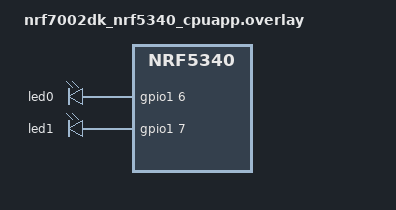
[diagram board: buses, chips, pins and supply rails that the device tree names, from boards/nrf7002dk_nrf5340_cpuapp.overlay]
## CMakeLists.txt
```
#
# Copyright (c) 2021 Nordic Semiconductor ASA
#
# SPDX-License-Identifier: LicenseRef-Nordic-5-Clause
#

cmake_minimum_required(VERSION 3.20.0)

# Set Kconfig root files that will be processed as a first Kconfig for used child images.
set(mcuboot_KCONFIG_ROOT "\\\${ZEPHYR_CONNECTEDHOMEIP_MODULE_DIR}/config/nrfconnect/chip-module/Kconfig.mcuboot.root")
set(multiprotocol_rpmsg_KCONFIG_ROOT "\\\${ZEPHYR_CONNECTEDHOMEIP_MODULE_DIR}/config/nrfconnect/chip-module/Kconfig.multiprotocol_rpmsg.root")
set(hci_ipc_KCONFIG_ROOT "\\\${ZEPHYR_CONNECTEDHOMEIP_MODULE_DIR}/config/nrfconnect/chip-module/Kconfig.hci_ipc.root")

# For prj.conf the CONF_FILE is empty. In other case extract the exact file name from the path string.
if(CONF_FILE)
    get_filename_component(CONF_FILE_NAME ${CONF_FILE} NAME CACHE)
endif()

if(NOT CONF_FILE_NAME STREQUAL "prj_no_dfu.conf")
    set(PM_STATIC_YML_FILE ${CMAKE_CURRENT_SOURCE_DIR}/configuration/${BOARD}/pm_static_dfu.yml)
endif()

if(CONF_FILE_NAME STREQUAL "prj_thread_wifi_switched.conf")
    # TODO: Add Kconfig for adding custom Matter compilation flags
    set(CHIP_CFLAGS "-flto")
endif()

find_package(Zephyr HINTS $ENV{ZEPHYR_BASE})

project(matter-lock)

set(COMMON_ROOT ${ZEPHYR_NRF_MODULE_DIR}/samples/matter/common)
set(NLIO_ROOT ${ZEPHYR_CONNECTEDHOMEIP_MODULE_DIR}/third_party/nlio/repo)
include(${ZEPHYR_CONNECTEDHOMEIP_MODULE_DIR}/config/nrfconnect/app/enable-gnu-std.cmake)
include(${ZEPHYR_CONNECTEDHOMEIP_MODULE_DIR}/src/app/chip_data_model.cmake)

# NORDIC SDK APP START
target_include_directories(app PRIVATE
    src
    ${COMMON_ROOT}/src
    ${NLIO_ROOT}/include
    ${ZEPHYR_CONNECTEDHOMEIP_MODULE_DIR}/zzz_generated/app-common
)

target_sources(app PRIVATE
    src/app_task.cpp
    src/bolt_lock_manager.cpp
    src/main.cpp
    src/zcl_callbacks.cpp
    ${COMMON_ROOT}/src/board/led_widget.cpp
    ${COMMON_ROOT}/src/app/task_executor.cpp
    ${COMMON_ROOT}/src/board/board.cpp
    ${COMMON_ROOT}/src/app/matter_init.cpp
    ${COMMON_ROOT}/src/app/matter_event_handler.cpp
)

if(CONFIG_CHIP_ICD_LIT_SUPPORT)
target_include_directories(app PRIVATE
    src/lit
)

target_sources(app PRIVATE
    src/lit/zap-generated/callback-stub.cpp
    src/lit/zap-generated/IMClusterCommandHandler.cpp
)
else()
target_include_directories(app PRIVATE
    src/sit
)

target_sources(app PRIVATE
    src/sit/zap-generated/callback-stub.cpp
    src/sit/zap-generated/IMClusterCommandHandler.cpp
)
endif()

if(CONFIG_CHIP_OTA_REQUESTOR OR CONFIG_MCUMGR_TRANSPORT_BT)
    target_sources(app PRIVATE ${COMMON_ROOT}/src/dfu/ota/ota_util.cpp)
endif()

if(CONFIG_CHIP_NUS)
    target_sources(app PRIVATE ${COMMON_ROOT}/src/bt_nus/bt_nus_service.cpp)
endif()

if(CONFIG_MCUMGR_TRANSPORT_BT)
    zephyr_library_link_libraries(MCUBOOT_BOOTUTIL)
    target_sources(app PRIVATE ${COMMON_ROOT}/src/dfu/smp/dfu_over_smp.cpp)
endif()

if(CONFIG_THREAD_WIFI_SWITCHING)
    target_sources(app PRIVATE src/thread_wifi_switch.cpp)

    # Enable link-time optimization for the app and WPA supplicant libraries
    target_compile_options(app PRIVATE -flto)
    target_compile_options(..__nrf__modules__hostap PRIVATE -flto)
endif()

if(CONFIG_NCS_SAMPLE_MATTER_OPERATIONAL_KEYS_MIGRATION_TO_ITS)
    target_sources(app PRIVATE ${COMMON_ROOT}/src/migration/migration_manager.cpp)
endif()

if(CONFIG_CHIP_ICD_LIT_SUPPORT)
chip_configure_data_model(app
    INCLUDE_SERVER
    BYPASS_IDL
    GEN_DIR src/lit/zap-generated
    ZAP_FILE ${CMAKE_CURRENT_SOURCE_DIR}/src/lock-lit.zap
)
else()
chip_configure_data_model(app
    INCLUDE_SERVER
    BYPASS_IDL
    GEN_DIR src/sit/zap-generated
    ZAP_FILE ${CMAKE_CURRENT_SOURCE_DIR}/src/lock.zap
)
endif()
# NORDIC SDK APP END
```

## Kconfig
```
#
# Copyright (c) 2021 Nordic Semiconductor
#
# SPDX-License-Identifier: LicenseRef-Nordic-5-Clause
#

mainmenu "Matter Lock sample application"

config STATE_LEDS
	bool "Use LEDs to indicate the device state"
	default y
	help
	  Use LEDs to render the current state of the device such as the progress of commissioning of
	  the device into a network or the factory reset initiation. Note that setting this option to
	  'n' does not disable the LED indicating the state of the simulated bolt.

rsource "${ZEPHYR_BASE}/../modules/lib/matter/config/nrfconnect/chip-module/Kconfig.features"
rsource "${ZEPHYR_BASE}/../modules/lib/matter/config/nrfconnect/chip-module/Kconfig.defaults"
source "Kconfig.zephyr"
```

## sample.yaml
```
sample:
  description: Matter Lock example
  name: Matter Lock
tests:
  sample.matter.lock.debug:
    sysbuild: true
    build_only: true
    integration_platforms:
      - nrf52840dk/nrf52840
      - nrf5340dk/nrf5340/cpuapp
      - nrf7002dk/nrf5340/cpuapp
      - nrf7002dk/nrf5340/cpuapp/nrf7001
      - nrf54l15dk/nrf54l15/cpuapp
      - nrf54l15dk/nrf54l15/cpuapp/ns
      - nrf54h20dk/nrf54h20/cpuapp
    platform_allow: nrf52840dk/nrf52840 nrf5340dk/nrf5340/cpuapp nrf7002dk/nrf5340/cpuapp
      nrf7002dk/nrf5340/cpuapp/nrf7001 nrf54l15dk/nrf54l15/cpuapp
      nrf54h20dk/nrf54h20/cpuapp nrf54l15dk/nrf54l15/cpuapp/ns
    tags: sysbuild ci_samples_matter
  sample.matter.lock.release:
    sysbuild: true
    build_only: true
    extra_args: FILE_SUFFIX=release
    integration_platforms:
      - nrf52840dk/nrf52840
      - nrf5340dk/nrf5340/cpuapp
      - nrf7002dk/nrf5340/cpuapp
      - nrf7002dk/nrf5340/cpuapp/nrf7001
      - nrf54l15dk/nrf54l15/cpuapp
      - nrf54h20dk/nrf54h20/cpuapp
    platform_allow: nrf52840dk/nrf52840 nrf5340dk/nrf5340/cpuapp nrf7002dk/nrf5340/cpuapp
      nrf7002dk/nrf5340/cpuapp/nrf7001 nrf54l15dk/nrf54l15/cpuapp
      nrf54h20dk/nrf54h20/cpuapp
    tags: sysbuild ci_samples_matter
  sample.matter.lock.lto:
    sysbuild: true
    build_only: true
    extra_args: CONFIG_LTO=y CONFIG_ISR_TABLES_LOCAL_DECLARATION=y
    integration_platforms:
      - nrf52840dk/nrf52840
      - nrf5340dk/nrf5340/cpuapp
      - nrf7002dk/nrf5340/cpuapp
      - nrf7002dk/nrf5340/cpuapp/nrf7001
      - nrf54l15dk/nrf54l15/cpuapp
    platform_allow: nrf52840dk/nrf52840 nrf5340dk/nrf5340/cpuapp nrf7002dk/nrf5340/cpuapp
      nrf7002dk/nrf5340/cpuapp/nrf7001 nrf54l15dk/nrf54l15/cpuapp
    tags: sysbuild ci_samples_matter
  sample.matter.lock.smp_dfu:
    sysbuild: true
    build_only: true
    extra_args: CONFIG_CHIP_DFU_OVER_BT_SMP=y
    integration_platforms:
      - nrf52840dk/nrf52840
      - nrf5340dk/nrf5340/cpuapp
      - nrf7002dk/nrf5340/cpuapp
      - nrf7002dk/nrf5340/cpuapp/nrf7001
      - nrf54l15dk/nrf54l15/cpuapp
    platform_allow: nrf52840dk/nrf52840 nrf5340dk/nrf5340/cpuapp nrf7002dk/nrf5340/cpuapp
      nrf7002dk/nrf5340/cpuapp/nrf7001 nrf54l15dk/nrf54l15/cpuapp
    tags: sysbuild ci_samples_matter
  sample.matter.lock.no_dfu.no_fd:
    sysbuild: true
    build_only: true
    extra_args: SB_CONFIG_MATTER_OTA=n
    integration_platforms:
      - nrf21540dk/nrf52840
    platform_allow: nrf21540dk/nrf52840
    tags: sysbuild ci_samples_matter
  sample.matter.lock.thread_wifi_switched.lto.smp_dfu:
    sysbuild: true
    build_only: true
    extra_args: lock_SHIELD=nrf7002ek
      FILE_SUFFIX=thread_wifi_switched SB_CONFIG_WIFI_PATCHES_EXT_FLASH_STORE=y
      SB_CONFIG_MCUBOOT_UPDATEABLE_IMAGES=3 CONFIG_CHIP_DFU_OVER_BT_SMP=y
      SB_CONFIG_WIFI_NRF70=y SB_CONFIG_DFU_MULTI_IMAGE_PACKAGE_WIFI_FW_PATCH=y
    integration_platforms:
      - nrf5340dk/nrf5340/cpuapp
    platform_allow: nrf5340dk/nrf5340/cpuapp
    tags: sysbuild ci_samples_matter
  sample.matter.lock.nus:
    sysbuild: true
    build_only: true
    extra_args: CONFIG_CHIP_NUS=y CONFIG_BT_FIXED_PASSKEY=y CONFIG_CHIP_NUS_FIXED_PASSKEY=112233
    integration_platforms:
      - nrf52840dk/nrf52840
      - nrf5340dk/nrf5340/cpuapp
    platform_allow: nrf52840dk/nrf52840 nrf5340dk/nrf5340/cpuapp nrf54l15dk/nrf54l15/cpuapp
    tags: sysbuild ci_samples_matter
  sample.matter.lock.release.power_consumption:
    sysbuild: true
    build_only: true
    extra_args: FILE_SUFFIX=max_tx_power
    integration_platforms:
      - nrf52840dk/nrf52840
      - nrf5340dk/nrf5340/cpuapp
      - nrf54l15dk/nrf54l15/cpuapp
    platform_allow: nrf52840dk/nrf52840 nrf5340dk/nrf5340/cpuapp nrf54l15dk/nrf54l15/cpuapp
    tags: sysbuild ci_samples_matter
```

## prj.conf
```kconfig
#
# Copyright (c) 2022 Nordic Semiconductor ASA
#
# SPDX-License-Identifier: LicenseRef-Nordic-5-Clause
#

# This sample uses Kconfig.defaults to set options common for all
# samples. This file should contain only options specific for this sample
# or overrides of default values.

# Enable CHIP
CONFIG_CHIP=y
CONFIG_CHIP_PROJECT_CONFIG="src/chip_project_config.h"
# 32774 == 0x8006 (example lock-app)
CONFIG_CHIP_DEVICE_PRODUCT_ID=32774
CONFIG_STD_CPP17=y

# Enable Matter extended announcement and increase duration to 1 hour.
CONFIG_CHIP_BLE_EXT_ADVERTISING=y
CONFIG_CHIP_BLE_ADVERTISING_DURATION=60

# Add support for LEDs and buttons on Nordic development kits
CONFIG_DK_LIBRARY=y

# Bluetooth Low Energy configuration
CONFIG_BT_DEVICE_NAME="MatterLock"

# Suspend devices when the CPU goes into sleep
CONFIG_PM_DEVICE=y

# Other settings
CONFIG_THREAD_NAME=y
CONFIG_MPU_STACK_GUARD=y
CONFIG_RESET_ON_FATAL_ERROR=n
CONFIG_CHIP_LIB_SHELL=y

# Reduce application size
CONFIG_USE_SEGGER_RTT=n
CONFIG_MATTER_LOG_LEVEL_INF=y
CONFIG_CHIP_APP_LOG_LEVEL=3

# Enable Factory Data feature
CONFIG_CHIP_FACTORY_DATA=y
CONFIG_CHIP_FACTORY_DATA_BUILD=y

# Increase system workqueue stack size
CONFIG_SYSTEM_WORKQUEUE_STACK_SIZE=1536

# Enable LIT ICD configuration
CONFIG_CHIP_ICD_LIT_SUPPORT=y
```

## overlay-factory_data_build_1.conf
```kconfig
#
# Copyright (c) 2023 Nordic Semiconductor ASA
#
# SPDX-License-Identifier: LicenseRef-Nordic-5-Clause
#

# Use this overlay to re-generate new PAI and DAC certificates.
# Be sure that chip-cert executable is added to your system PATH.

# Enable building the new factory data
CONFIG_CHIP_FACTORY_DATA=y
CONFIG_CHIP_FACTORY_DATA_BUILD=y
CONFIG_CHIP_FACTORY_DATA_USE_DEFAULT_CERTS=n
CONFIG_CHIP_FACTORY_DATA_CERT_SOURCE_GENERATED=y
CONFIG_CHIP_FACTORY_DATA_MERGE_WITH_FIRMWARE=y
CONFIG_CHIP_DEVICE_GENERATE_ROTATING_DEVICE_UID=n

# Set up the Factory Data
CONFIG_CHIP_DEVICE_SERIAL_NUMBER="1"
CONFIG_CHIP_DEVICE_VENDOR_ID=65521
CONFIG_CHIP_DEVICE_VENDOR_NAME="Nordic Semiconductor ASA"
CONFIG_CHIP_DEVICE_PRODUCT_ID=32774
CONFIG_CHIP_DEVICE_PRODUCT_NAME="Door Lock"
CONFIG_CHIP_DEVICE_MANUFACTURING_DATE="2023-05-30"
CONFIG_CHIP_DEVICE_HARDWARE_VERSION=1
CONFIG_CHIP_DEVICE_HARDWARE_VERSION_STRING="TE1_2023"
CONFIG_CHIP_DEVICE_DISCRIMINATOR=0xE46
CONFIG_CHIP_DEVICE_SPAKE2_PASSCODE=28073715
CONFIG_CHIP_DEVICE_SPAKE2_IT=1000
CONFIG_CHIP_DEVICE_SPAKE2_TEST_VERIFIER="XUQaKLznAVZ+WEWkSTIEJwvjaU/CuWY1qLbRKuS56VEE4Us+aJNGy3B3tLClZWRDAS5yXUgku5pHyFLgVTAKXQIo663Y2L7HvrJh/8jlD0OTNDDLlsnjKdj+l0b2rC3vMg=="
CONFIG_CHIP_DEVICE_ROTATING_DEVICE_UID="0989f27796617e00ff9dc844496dbcf3"
CONFIG_CHIP_DEVICE_ENABLE_KEY="d229322af1412d66ebeda07e0d39b80e"
CONFIG_CHIP_DEVICE_PRODUCT_FINISH="other"
CONFIG_CHIP_DEVICE_PRODUCT_COLOR="aqua"

CONFIG_CHIP_FACTORY_DATA_CERT_SOURCE_USER=y
# Align paths to your local ones
CONFIG_CHIP_FACTORY_DATA_USER_CERTS_DAC_CERT="~/ncs/nrf/samples/matter/lock/factory_data_1/DAC-Cert.der"
CONFIG_CHIP_FACTORY_DATA_USER_CERTS_DAC_KEY="~/ncs/nrf/samples/matter/lock/factory_data_1/DAC-Key.der"
CONFIG_CHIP_FACTORY_DATA_USER_CERTS_PAI_CERT="~/ncs/nrf/samples/matter/lock/factory_data_1//PAI-Cert.der"
```

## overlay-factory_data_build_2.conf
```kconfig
#
# Copyright (c) 2023 Nordic Semiconductor ASA
#
# SPDX-License-Identifier: LicenseRef-Nordic-5-Clause
#

# Use this overlay to re-generate new PAI and DAC certificates.
# Be sure that chip-cert executable is added to your system PATH.

# Enable building the new factory data
CONFIG_CHIP_FACTORY_DATA=y
CONFIG_CHIP_FACTORY_DATA_BUILD=y
CONFIG_CHIP_FACTORY_DATA_USE_DEFAULT_CERTS=n
CONFIG_CHIP_FACTORY_DATA_CERT_SOURCE_GENERATED=y
CONFIG_CHIP_FACTORY_DATA_MERGE_WITH_FIRMWARE=y
CONFIG_CHIP_DEVICE_GENERATE_ROTATING_DEVICE_UID=n

# Set up the Factory Data
CONFIG_CHIP_DEVICE_SERIAL_NUMBER="2"
CONFIG_CHIP_DEVICE_VENDOR_ID=65521
CONFIG_CHIP_DEVICE_VENDOR_NAME="Nordic Semiconductor ASA"
CONFIG_CHIP_DEVICE_PRODUCT_ID=32774
CONFIG_CHIP_DEVICE_PRODUCT_NAME="Door Lock"
CONFIG_CHIP_DEVICE_MANUFACTURING_DATE="2023-05-30"
CONFIG_CHIP_DEVICE_HARDWARE_VERSION=1
CONFIG_CHIP_DEVICE_HARDWARE_VERSION_STRING="TE1_2023"
CONFIG_CHIP_DEVICE_DISCRIMINATOR=0x1fa
CONFIG_CHIP_DEVICE_SPAKE2_PASSCODE=80327003
CONFIG_CHIP_DEVICE_SPAKE2_IT=1000
CONFIG_CHIP_DEVICE_SPAKE2_TEST_VERIFIER="sMpmMvNf6t1TROKCjV9CnYwCMMV7l5YyXX/ajicjG1MEkZx8Ylg73OpW6w+BpfWeFgUBHreWf166zwxaTaY53y6cIFnu9HvWQofN0yKmnRjDZyZpBpb+2pR7bIdqUxcHcw=="
CONFIG_CHIP_DEVICE_ROTATING_DEVICE_UID="462a2785f8536233d6ce0427970fc596"
CONFIG_CHIP_DEVICE_ENABLE_KEY="5a9f1b3e358cc9934900aa6a2a085024"
CONFIG_CHIP_DEVICE_PRODUCT_FINISH="other"
CONFIG_CHIP_DEVICE_PRODUCT_COLOR="aqua"

CONFIG_CHIP_FACTORY_DATA_CERT_SOURCE_USER=y
# Align paths to your local ones
CONFIG_CHIP_FACTORY_DATA_USER_CERTS_DAC_CERT="~/ncs/nrf/samples/matter/lock/factory_data_2/DAC-Cert.der"
CONFIG_CHIP_FACTORY_DATA_USER_CERTS_DAC_KEY="~/ncs/nrf/samples/matter/lock/factory_data_2/DAC-Key.der"
CONFIG_CHIP_FACTORY_DATA_USER_CERTS_PAI_CERT="~/ncs/nrf/samples/matter/lock/factory_data_2//PAI-Cert.der"
```

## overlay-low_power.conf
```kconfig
#
# Copyright (c) 2021 Nordic Semiconductor
#
# SPDX-License-Identifier: LicenseRef-Nordic-5-Clause
#

# Enable MTD Sleepy End Device
CONFIG_CHIP_ENABLE_SLEEPY_END_DEVICE_SUPPORT=y

# SED requires less aggresive BLE connection intervals
CONFIG_BT_PERIPHERAL_PREF_MIN_INT=36
CONFIG_BT_PERIPHERAL_PREF_MAX_INT=36

# Disable UART console
# CONFIG_SHELL=n
# CONFIG_LOG=n
# CONFIG_UART_CONSOLE=n
# CONFIG_SERIAL=n
CONFIG_CHIP_DEVICE_SOFTWARE_VERSION=2

# Suspend devices when the CPU goes into sleep
CONFIG_PM_DEVICE=y

# Disable auxiliary state LEDs
CONFIG_STATE_LEDS=n
```

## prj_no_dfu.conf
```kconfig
#
# Copyright (c) 2022 Nordic Semiconductor ASA
#
# SPDX-License-Identifier: LicenseRef-Nordic-5-Clause
#

# This sample uses Kconfig.defaults to set options common for all
# samples. This file should contain only options specific for this sample
# or overrides of default values.

# Enable CHIP
CONFIG_CHIP=y
CONFIG_CHIP_PROJECT_CONFIG="src/chip_project_config.h"
# 32774 == 0x8006 (example lock-app)
CONFIG_CHIP_DEVICE_PRODUCT_ID=32774
CONFIG_STD_CPP14=y

# Add support for LEDs and buttons on Nordic development kits
CONFIG_DK_LIBRARY=y

# Bluetooth Low Energy configuration
CONFIG_BT_DEVICE_NAME="MatterLock"

# Other settings
CONFIG_THREAD_NAME=y
CONFIG_MPU_STACK_GUARD=y
CONFIG_RESET_ON_FATAL_ERROR=n

# Disable Matter OTA DFU
CONFIG_CHIP_OTA_REQUESTOR=n

# Disable QSPI NOR
CONFIG_CHIP_QSPI_NOR=n
CONFIG_BT_HCI_VS=y
CONFIG_BT_CTLR_TX_PWR_DYNAMIC_CONTROL=y
```

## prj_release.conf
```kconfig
#
# Copyright (c) 2022 Nordic Semiconductor ASA
#
# SPDX-License-Identifier: LicenseRef-Nordic-5-Clause
#

# This sample uses Kconfig.defaults to set options common for all
# samples. This file should contain only options specific for this sample
# or overrides of default values.

# Enable CHIP
CONFIG_CHIP=y
CONFIG_CHIP_PROJECT_CONFIG="src/chip_project_config.h"
# 32774 == 0x8006 (example lock-app)
CONFIG_CHIP_DEVICE_PRODUCT_ID=32774
CONFIG_STD_CPP17=y

# Enable Matter extended announcement and increase duration to 1 hour.
CONFIG_CHIP_BLE_EXT_ADVERTISING=y
CONFIG_CHIP_BLE_ADVERTISING_DURATION=60

# Add support for LEDs and buttons on Nordic development kits
CONFIG_DK_LIBRARY=y

# Bluetooth Low Energy configuration
CONFIG_BT_DEVICE_NAME="MatterLock"

# Suspend devices when the CPU goes into sleep
CONFIG_PM_DEVICE=y

# Enable system reset on fatal error
CONFIG_RESET_ON_FATAL_ERROR=y

# Try to disable unused RAM blocks to reduce power consumption
CONFIG_RAM_POWER_DOWN_LIBRARY=y

# Disable all debug features
CONFIG_USE_SEGGER_RTT=n
CONFIG_SHELL=n
CONFIG_OPENTHREAD_SHELL=n
CONFIG_CONSOLE=n
CONFIG_UART_CONSOLE=n
CONFIG_SERIAL=n
CONFIG_LOG=n
CONFIG_LOG_MODE_MINIMAL=n
CONFIG_ASSERT_VERBOSE=n
CONFIG_ASSERT_NO_FILE_INFO=y
CONFIG_PRINTK=n
CONFIG_PRINTK_SYNC=n
CONFIG_THREAD_NAME=n
CONFIG_BOOT_BANNER=n

# Enable Factory Data feature
CONFIG_CHIP_FACTORY_DATA=y
CONFIG_CHIP_FACTORY_DATA_BUILD=y

# Enable Watchdog
CONFIG_NCS_SAMPLE_MATTER_WATCHDOG=y

CONFIG_CHIP_ICD_SLOW_POLL_INTERVAL=1000
CONFIG_CHIP_ICD_FAST_POLLING_INTERVAL=200
CONFIG_CHIP_ICD_IDLE_MODE_DURATION=120
CONFIG_CHIP_ICD_ACTIVE_MODE_DURATION=300
CONFIG_CHIP_ICD_ACTIVE_MODE_THRESHOLD=300

CONFIG_CHIP_PERSISTENT_SUBSCRIPTIONS=y
CONFIG_CHIP_ENABLE_PAIRING_AUTOSTART=y
```

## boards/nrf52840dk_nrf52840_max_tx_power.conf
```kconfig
#
# Copyright (c) 2022 Nordic Semiconductor ASA
#
# SPDX-License-Identifier: LicenseRef-Nordic-5-Clause
#

# This sample uses Kconfig.defaults to set options common for all
# samples. This file should contain only options specific for this sample
# or overrides of default values.

CONFIG_OPENTHREAD_DEFAULT_TX_POWER=8
```

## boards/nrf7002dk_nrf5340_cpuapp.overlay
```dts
/*
 * Copyright (c) 2022 Nordic Semiconductor ASA
 *
 * SPDX-License-Identifier: LicenseRef-Nordic-5-Clause
 */

&led0 {
    gpios = <&gpio1 6 GPIO_ACTIVE_HIGH>;
};

&led1 {
    gpios = <&gpio1 7 GPIO_ACTIVE_HIGH>;
};
```

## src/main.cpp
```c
/*
 * Copyright (c) 2021 Nordic Semiconductor ASA
 *
 * SPDX-License-Identifier: LicenseRef-Nordic-5-Clause
 */

#include "app_task.h"

#include <logging/log.h>

#include <lib/support/CHIPMem.h>
#include <platform/CHIPDeviceLayer.h>

#include "drivers/gpio.h"
#include "mpsl_radio_notification.h"

LOG_MODULE_REGISTER(app);

using namespace ::chip::DeviceLayer;

// TODO: Pin number should be changed to the one connected to the FEM
const char *kGPIOControllerName = "GPIO_0";
gpio_pin_t kFemControlPin = 13;
const struct device *kGPIOController = device_get_binding(kGPIOControllerName);
static bool sFemPinConfigured;
static bool sRadioActive;

static void power_management_irq(void)
{
	if (sRadioActive) {
		LOG_INF("Radio goes active");
	} else {
		LOG_INF("Radio goes inactive");
	}
	sRadioActive = !sRadioActive;

	// Change FEM enabling pin state
	if (sFemPinConfigured) {
		gpio_pin_toggle(kGPIOController, kFemControlPin);
	}
}

static int power_management_hook_init(const struct device *dev)
{
	int res = mpsl_radio_notification_cfg_set(MPSL_RADIO_NOTIFICATION_TYPE_INT_ON_BOTH,
						  MPSL_RADIO_NOTIFICATION_DISTANCE_200US, SWI2_IRQn);

	if (res) {
		LOG_ERR("mpsl_radio_notification_cfg_set failed with %d", res);
		return -1;
	}

	NVIC_ClearPendingIRQ(SWI2_IRQn);
	NVIC_SetPriority(SWI2_IRQn, 4);
	NVIC_EnableIRQ(SWI2_IRQn);

	IRQ_CONNECT(SWI2_IRQn, 4, power_management_irq, NULL, 0);

	return 0;
}


int main()
{
	int ret = 0;
	CHIP_ERROR err = CHIP_NO_ERROR;

	err = chip::Platform::MemoryInit();
	if (err != CHIP_NO_ERROR) {
		LOG_ERR("Platform::MemoryInit() failed");
		goto exit;
	}

	if (kGPIOController) {
		if (gpio_pin_configure(kGPIOController, kFemControlPin, GPIO_OUTPUT_ACTIVE)) {
			LOG_ERR("Cannot configure kFemControlPin");
		} else {
			if (gpio_pin_set(kGPIOController, kFemControlPin, 0)) {
				LOG_ERR("Cannot set kFemControlPin");
			} else {
				sFemPinConfigured = true;
			}
		}
	} else {
		LOG_ERR("Cannot find kGPIOController");
	}

	LOG_INF("Init CHIP stack");
	err = PlatformMgr().InitChipStack();
	if (err != CHIP_NO_ERROR) {
		LOG_ERR("PlatformMgr().InitChipStack() failed");
		goto exit;
	}

	LOG_INF("Starting CHIP task");
	err = PlatformMgr().StartEventLoopTask();
	if (err != CHIP_NO_ERROR) {
		LOG_ERR("PlatformMgr().StartEventLoopTask() failed");
		goto exit;
	}

	LOG_INF("Init Thread stack");
	err = ThreadStackMgr().InitThreadStack();
	if (err != CHIP_NO_ERROR) {
		LOG_ERR("ThreadStackMgr().InitThreadStack() failed");
		goto exit;
	}

#ifdef CONFIG_OPENTHREAD_MTD_SED
	err = ConnectivityMgr().SetThreadDeviceType(ConnectivityManager::kThreadDeviceType_SleepyEndDevice);
	if (err != CHIP_NO_ERROR) {
		LOG_ERR("ConnectivityMgr().SetThreadDeviceType() failed");
		goto exit;
	}

	ConnectivityManager::ThreadPollingConfig pollingConfig;
	pollingConfig.Clear();
	pollingConfig.ActivePollingIntervalMS = CONFIG_OPENTHREAD_POLL_PERIOD;
	pollingConfig.InactivePollingIntervalMS = CONFIG_OPENTHREAD_POLL_PERIOD;

	err = ConnectivityMgr().SetThreadPollingConfig(pollingConfig);
	if (err != CHIP_NO_ERROR) {
		LOG_ERR("ConnectivityMgr().SetThreadPollingConfig() failed");
		goto exit;
	}
#else
	err = ConnectivityMgr().SetThreadDeviceType(ConnectivityManager::kThreadDeviceType_MinimalEndDevice);
	if (err != CHIP_NO_ERROR) {
		LOG_ERR("ConnectivityMgr().SetThreadDeviceType() failed");
		goto exit;
	}
#endif
	ret = GetAppTask().StartApp();
	if (ret != 0) {
		err = chip::System::MapErrorZephyr(ret);
	}

exit:
	return err == CHIP_NO_ERROR ? EXIT_SUCCESS : EXIT_FAILURE;
}

SYS_INIT(power_management_hook_init, POST_KERNEL, CONFIG_KERNEL_INIT_PRIORITY_DEFAULT);
```

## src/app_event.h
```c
/*
 * Copyright (c) 2021 Nordic Semiconductor ASA
 *
 * SPDX-License-Identifier: LicenseRef-Nordic-5-Clause
 */

#pragma once

#include <cstdint>

#include "led_widget.h"

struct AppEvent;
typedef void (*EventHandler)(const AppEvent &);

struct AppEvent {
	enum AppEventType {
		Button = 0,
		Timer,
		Lock,
		UpdateLedState,
#ifdef CONFIG_MCUMGR_SMP_BT
		StartSMPAdvertising,
#endif
	};

	// 	enum LockEventType : uint8_t { Lock, Unlock, Toggle, CompleteLockAction };

	// 	enum FunctionEventType : uint8_t { FunctionPress = CompleteLockAction + 1, FunctionRelease,
	// FunctionTimer };

	// 	enum UpdateLedStateEventType : uint8_t { UpdateLedState = FunctionTimer + 1 };

	// 	enum OtherEventType : uint8_t {
	// 		StartBleAdvertising = UpdateLedState + 1,
	// #ifdef CONFIG_MCUMGR_SMP_BT
	// 		StartSMPAdvertising
	// #endif
	// 	};

	// AppEvent() = default;
	// AppEvent(LockEventType type, BoltLockManager::OperationSource source) : Type(type), LockEvent{ source } {}
	// AppEvent(FunctionEventType type, uint8_t buttonNumber) : Type(type), FunctionEvent{ buttonNumber } {}
	// AppEvent(UpdateLedStateEventType type, LEDWidget *ledWidget) : Type(type), UpdateLedStateEvent{ ledWidget }
	// {} explicit AppEvent(OtherEventType type) : Type(type) {}

	// uint8_t Type;

	// union {
	// 	struct {
	// 		BoltLockManager::OperationSource Source;
	// 	} LockEvent;
	// 	struct {
	// 		LEDWidget *LedWidget;
	// 	} UpdateLedStateEvent;
	// 	struct {
	// 		uint8_t ButtonNumber;
	// 	} FunctionEvent;
	// };
	uint16_t Type;

	union {
		struct {
			uint8_t PinNo;
			uint8_t Action;
		} ButtonEvent;
		struct {
			void *Context;
		} TimerEvent;
		struct {
			uint8_t Action;
			int32_t Actor;
		} LockEvent;
		struct {
			LEDWidget *LedWidget;
		} UpdateLedStateEvent;
	};

	EventHandler Handler;
};
```

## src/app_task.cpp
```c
/*
 * Copyright (c) 2021 Nordic Semiconductor ASA
 *
 * SPDX-License-Identifier: LicenseRef-Nordic-5-Clause
 */

#include "app_task.h"

#include "bolt_lock_manager.h"

#ifdef CONFIG_THREAD_WIFI_SWITCHING
#include "thread_wifi_switch.h"
#endif

#include "app/matter_init.h"
#include "app/task_executor.h"

#ifdef CONFIG_CHIP_NUS
#include "bt_nus/bt_nus_service.h"
#endif

#ifdef CONFIG_CHIP_OTA_REQUESTOR
#include "dfu/ota/ota_util.h"
#endif

#include <app-common/zap-generated/attributes/Accessors.h>
#include <app/clusters/door-lock-server/door-lock-server.h>
#include <app/clusters/identify-server/identify-server.h>
#include <app/server/OnboardingCodesUtil.h>
#include <platform/CHIPDeviceLayer.h>

#include <zephyr/logging/log.h>

LOG_MODULE_DECLARE(app, CONFIG_CHIP_APP_LOG_LEVEL);

using namespace ::chip;
using namespace ::chip::app;
using namespace ::chip::DeviceLayer;

namespace
{
constexpr EndpointId kLockEndpointId = 1;

#ifdef CONFIG_CHIP_NUS
constexpr uint16_t kAdvertisingIntervalMin = 400;
constexpr uint16_t kAdvertisingIntervalMax = 500;
constexpr uint8_t kLockNUSPriority = 2;
#endif

#ifdef CONFIG_THREAD_WIFI_SWITCHING
k_timer sSwitchTransportTimer;
constexpr uint32_t kSwitchTransportTimeout = 10000;
#endif

#define APPLICATION_BUTTON_MASK DK_BTN2_MSK
#define SWITCHING_BUTTON_MASK DK_BTN3_MSK
} /* namespace */

#ifdef CONFIG_NCS_SAMPLE_MATTER_LEDS
Identify sIdentify = { kLockEndpointId, AppTask::IdentifyStartHandler, AppTask::IdentifyStopHandler,
		       Clusters::Identify::IdentifyTypeEnum::kVisibleIndicator };

void AppTask::IdentifyStartHandler(Identify *)
{
	Nrf::PostTask(
		[] { Nrf::GetBoard().GetLED(Nrf::DeviceLeds::LED2).Blink(Nrf::LedConsts::kIdentifyBlinkRate_ms); });
}

void AppTask::IdentifyStopHandler(Identify *)
{
	Nrf::PostTask([] { Nrf::GetBoard().GetLED(Nrf::DeviceLeds::LED2).Set(BoltLockMgr().IsLocked()); });
}
#endif /* CONFIG_NCS_SAMPLE_MATTER_LEDS */

void AppTask::ButtonEventHandler(Nrf::ButtonState state, Nrf::ButtonMask hasChanged)
{
	if ((APPLICATION_BUTTON_MASK & hasChanged) & state) {
		Nrf::PostTask([] { LockActionEventHandler(); });
	}

#ifdef CONFIG_THREAD_WIFI_SWITCHING
	if (SWITCHING_BUTTON_MASK & hasChanged) {
		SwitchButtonAction action =
			(SWITCHING_BUTTON_MASK & state) ? SwitchButtonAction::Pressed : SwitchButtonAction::Released;
		Nrf::PostTask([action] { SwitchTransportTriggerHandler(action); });
	}
#endif
}

void AppTask::LockActionEventHandler()
{
	if (BoltLockMgr().IsLocked()) {
		BoltLockMgr().Unlock(BoltLockManager::OperationSource::kButton);
	} else {
		BoltLockMgr().Lock(BoltLockManager::OperationSource::kButton);
	}
}

#ifdef CONFIG_THREAD_WIFI_SWITCHING
void AppTask::SwitchTransportEventHandler()
{
	LOG_INF("Switching to %s", ThreadWifiSwitch::IsThreadActive() ? "Wi-Fi" : "Thread");

	ThreadWifiSwitch::SwitchTransport();
}

void AppTask::SwitchTransportTimerTimeoutCallback(k_timer *timer)
{
	Nrf::PostTask([] { SwitchTransportEventHandler(); });
}

void AppTask::SwitchTransportTriggerHandler(const SwitchButtonAction &action)
{
	if (action == SwitchButtonAction::Pressed) {
		LOG_INF("Keep button pressed for %u ms to switch to %s", kSwitchTransportTimeout,
			ThreadWifiSwitch::IsThreadActive() ? "Wi-Fi" : "Thread");
		k_timer_start(&sSwitchTransportTimer, K_MSEC(kSwitchTransportTimeout), K_NO_WAIT);
	} else {
		LOG_INF("Switching to %s cancelled", ThreadWifiSwitch::IsThreadActive() ? "Wi-Fi" : "Thread");
		k_timer_stop(&sSwitchTransportTimer);
	}
}
#endif

void AppTask::LockStateChanged(BoltLockManager::State state, BoltLockManager::OperationSource source)
{
	switch (state) {
	case BoltLockManager::State::kLockingInitiated:
		LOG_INF("Lock action initiated");
#ifdef CONFIG_NCS_SAMPLE_MATTER_LEDS
		Nrf::GetBoard().GetLED(Nrf::DeviceLeds::LED2).Blink(50, 50);
#endif /* CONFIG_NCS_SAMPLE_MATTER_LEDS */
#ifdef CONFIG_CHIP_NUS
		Nrf::GetNUSService().SendData("locking", sizeof("locking"));
#endif
		break;
	case BoltLockManager::State::kLockingCompleted:
		LOG_INF("Lock action completed");
#ifdef CONFIG_NCS_SAMPLE_MATTER_LEDS
		Nrf::GetBoard().GetLED(Nrf::DeviceLeds::LED2).Set(true);
#endif /* CONFIG_NCS_SAMPLE_MATTER_LEDS */
#ifdef CONFIG_CHIP_NUS
		Nrf::GetNUSService().SendData("locked", sizeof("locked"));
#endif
		break;
	case BoltLockManager::State::kUnlockingInitiated:
		LOG_INF("Unlock action initiated");
#ifdef CONFIG_NCS_SAMPLE_MATTER_LEDS
		Nrf::GetBoard().GetLED(Nrf::DeviceLeds::LED2).Blink(50, 50);
#endif /* CONFIG_NCS_SAMPLE_MATTER_LEDS */
#ifdef CONFIG_CHIP_NUS
		Nrf::GetNUSService().SendData("unlocking", sizeof("unlocking"));
#endif
		break;
	case BoltLockManager::State::kUnlockingCompleted:
		LOG_INF("Unlock action completed");
#ifdef CONFIG_CHIP_NUS
		Nrf::GetNUSService().SendData("unlocked", sizeof("unlocked"));
#endif
#ifdef CONFIG_NCS_SAMPLE_MATTER_LEDS
		Nrf::GetBoard().GetLED(Nrf::DeviceLeds::LED2).Set(false);
#endif /* CONFIG_NCS_SAMPLE_MATTER_LEDS */
		break;
	}

	/* Handle changing attribute state in the application */
	Instance().UpdateClusterState(state, source);
}

void AppTask::UpdateClusterState(BoltLockManager::State state, BoltLockManager::OperationSource source)
{
	DlLockState newLockState;

	switch (state) {
	case BoltLockManager::State::kLockingCompleted:
		newLockState = DlLockState::kLocked;
		break;
	case BoltLockManager::State::kUnlockingCompleted:
		newLockState = DlLockState::kUnlocked;
		break;
	default:
		newLockState = DlLockState::kNotFullyLocked;
		break;
	}

	SystemLayer().ScheduleLambda([newLockState, source] {
		chip::app::DataModel::Nullable<chip::app::Clusters::DoorLock::DlLockState> currentLockState;
		chip::app::Clusters::DoorLock::Attributes::LockState::Get(kLockEndpointId, currentLockState);

		if (currentLockState.IsNull()) {
			/* Initialize lock state with start value, but not invoke lock/unlock. */
			chip::app::Clusters::DoorLock::Attributes::LockState::Set(kLockEndpointId, newLockState);
		} else {
			LOG_INF("Updating LockState attribute");

			if (!DoorLockServer::Instance().SetLockState(kLockEndpointId, newLockState, source)) {
				LOG_ERR("Failed to update LockState attribute");
			}
		}
	});
}

#ifdef CONFIG_CHIP_NUS
void AppTask::NUSLockCallback(void *context)
{
	LOG_DBG("Received LOCK command from NUS");
	if (BoltLockMgr().mState == BoltLockManager::State::kLockingCompleted ||
	    BoltLockMgr().mState == BoltLockManager::State::kLockingInitiated) {
		LOG_INF("Device is already locked");
	} else {
		Nrf::PostTask([] { LockActionEventHandler(); });
	}
}

void AppTask::NUSUnlockCallback(void *context)
{
	LOG_DBG("Received UNLOCK command from NUS");
	if (BoltLockMgr().mState == BoltLockManager::State::kUnlockingCompleted ||
	    BoltLockMgr().mState == BoltLockManager::State::kUnlockingInitiated) {
		LOG_INF("Device is already unlocked");
	} else {
		Nrf::PostTask([] { LockActionEventHandler(); });
	}
}
#endif

#ifdef CONFIG_NCS_SAMPLE_MATTER_TEST_EVENT_TRIGGERS
CHIP_ERROR AppTask::DoorLockJammedEventCallback(Nrf::Matter::TestEventTrigger::TriggerValue)
{
	VerifyOrReturnError(DoorLockServer::Instance().SendLockAlarmEvent(kLockEndpointId, AlarmCodeEnum::kLockJammed),
			    CHIP_ERROR_INTERNAL);
	LOG_ERR("Event Trigger: Doorlock jammed.");
	return CHIP_NO_ERROR;
}
#endif

CHIP_ERROR AppTask::Init()
{
	/* Initialize Matter stack */
#ifdef CONFIG_THREAD_WIFI_SWITCHING
	/* In the Thread/Wi-Fi switchable mode, it is the ThreadWifiSwitch module that owns the NetworkCommissioning
	   instances, so offload the initialization module from controlling that by explicitly setting the
	   mNetworkingInstance parameter to nullptr. Otherwise, the initialization module instantiates the
	   NetworkCommissioning object and handles it by default internally. */
	ReturnErrorOnFailure(Nrf::Matter::PrepareServer(Nrf::Matter::InitData{ .mNetworkingInstance = nullptr }));
#else
	ReturnErrorOnFailure(Nrf::Matter::PrepareServer());
#endif

	if (!Nrf::GetBoard().Init(ButtonEventHandler)) {
		LOG_ERR("User interface initialization failed.");
		return CHIP_ERROR_INCORRECT_STATE;
	}

	/* Register Matter event handler that controls the connectivity status LED based on the captured Matter network
	 * state. */
	ReturnErrorOnFailure(Nrf::Matter::RegisterEventHandler(Nrf::Board::DefaultMatterEventHandler, 0));

#ifdef CONFIG_THREAD_WIFI_SWITCHING
	CHIP_ERROR err = ThreadWifiSwitch::StartCurrentTransport();
	if (err != CHIP_NO_ERROR) {
		LOG_ERR("ThreadWifiSwitch::StartCurrentTransport() failed: %" CHIP_ERROR_FORMAT, err.Format());
		return err;
	}

	k_timer_init(&sSwitchTransportTimer, &AppTask::SwitchTransportTimerTimeoutCallback, nullptr);
#endif

#ifdef CONFIG_CHIP_NUS
	/* Initialize Nordic UART Service for Lock purposes */
	if (!Nrf::GetNUSService().Init(kLockNUSPriority, kAdvertisingIntervalMin, kAdvertisingIntervalMax)) {
		ChipLogError(Zcl, "Cannot initialize NUS service");
	}
	Nrf::GetNUSService().RegisterCommand("Lock", sizeof("Lock"), NUSLockCallback, nullptr);
	Nrf::GetNUSService().RegisterCommand("Unlock", sizeof("Unlock"), NUSUnlockCallback, nullptr);
	if (!Nrf::GetNUSService().StartServer()) {
		LOG_ERR("GetNUSService().StartServer() failed");
	}
#endif

	/* Initialize lock manager */
	BoltLockMgr().Init(LockStateChanged);

	/* Register Door Lock test event trigger */
#ifdef CONFIG_NCS_SAMPLE_MATTER_TEST_EVENT_TRIGGERS
	ReturnErrorOnFailure(Nrf::Matter::TestEventTrigger::Instance().RegisterTestEventTrigger(
		kDoorLockJammedEventTriggerId,
		Nrf::Matter::TestEventTrigger::EventTrigger{ 0, DoorLockJammedEventCallback }));
#endif

	return Nrf::Matter::StartServer();
}

CHIP_ERROR AppTask::StartApp()
{
	ReturnErrorOnFailure(Init());

	while (true) {
		Nrf::DispatchNextTask();
	}

	return CHIP_NO_ERROR;
}
```

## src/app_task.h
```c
/*
 * Copyright (c) 2021 Nordic Semiconductor ASA
 *
 * SPDX-License-Identifier: LicenseRef-Nordic-5-Clause
 */

#pragma once

#include "board/board.h"
#include "board/led_widget.h"
#include "bolt_lock_manager.h"

struct k_timer;
struct Identify;

#ifdef CONFIG_THREAD_WIFI_SWITCHING
enum class SwitchButtonAction : uint8_t { Pressed, Released };
#endif

class AppTask {
public:
	static AppTask &Instance()
	{
		static AppTask sAppTask;
		return sAppTask;
	};

	CHIP_ERROR StartApp();

	void UpdateClusterState(BoltLockManager::State state, BoltLockManager::OperationSource source);
	static void IdentifyStartHandler(Identify *);
	static void IdentifyStopHandler(Identify *);

private:
	CHIP_ERROR Init();

	static void LockActionEventHandler();
	static void ButtonEventHandler(Nrf::ButtonState state, Nrf::ButtonMask hasChanged);
	static void LockStateChanged(BoltLockManager::State state, BoltLockManager::OperationSource source);

#ifdef CONFIG_THREAD_WIFI_SWITCHING
	static void SwitchTransportEventHandler();
	static void SwitchTransportTimerTimeoutCallback(k_timer *timer);
	static void SwitchTransportTriggerHandler(const SwitchButtonAction &action);
#endif

#ifdef CONFIG_CHIP_ICD_UAT_SUPPORT
	static void IcdUatEventHandler();
#endif

#ifdef CONFIG_CHIP_NUS
	static void NUSLockCallback(void *context);
	static void NUSUnlockCallback(void *context);
#endif
};
```

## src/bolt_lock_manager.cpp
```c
/*
 * Copyright (c) 2021 Nordic Semiconductor ASA
 *
 * SPDX-License-Identifier: LicenseRef-Nordic-5-Clause
 */

#include "bolt_lock_manager.h"
#include "app/task_executor.h"

#include "app_task.h"

using namespace chip;

BoltLockManager BoltLockManager::sLock;

void BoltLockManager::Init(StateChangeCallback callback)
{
	mStateChangeCallback = callback;

	k_timer_init(&mActuatorTimer, &BoltLockManager::ActuatorTimerEventHandler, nullptr);
	k_timer_user_data_set(&mActuatorTimer, this);

	AccessMgr::Instance().Init();

#ifdef CONFIG_NCS_SAMPLE_MATTER_LEDS
	/* Set the default state */
	Nrf::GetBoard().GetLED(Nrf::DeviceLeds::LED2).Set(IsLocked());
#endif /* CONFIG_NCS_SAMPLE_MATTER_LEDS */
}

bool BoltLockManager::GetUser(uint16_t userIndex, EmberAfPluginDoorLockUserInfo &user)
{
	return AccessMgr::Instance().GetUserInfo(userIndex, user);
}

bool BoltLockManager::SetUser(uint16_t userIndex, FabricIndex creator, FabricIndex modifier, const CharSpan &userName,
			      uint32_t uniqueId, UserStatusEnum userStatus, UserTypeEnum userType,
			      CredentialRuleEnum credentialRule, const CredentialStruct *credentials,
			      size_t totalCredentials)
{
	return AccessMgr::Instance().SetUser(userIndex, creator, modifier, userName, uniqueId, userStatus, userType,
					     credentialRule, credentials, totalCredentials);
}

bool BoltLockManager::GetCredential(uint16_t credentialIndex, CredentialTypeEnum credentialType,
				    EmberAfPluginDoorLockCredentialInfo &credential)
{
	return AccessMgr::Instance().GetCredential(credentialIndex, credentialType, credential);
}

bool BoltLockManager::SetCredential(uint16_t credentialIndex, FabricIndex creator, FabricIndex modifier,
				    DlCredentialStatus credentialStatus, CredentialTypeEnum credentialType,
				    const ByteSpan &secret)
{
	return AccessMgr::Instance().SetCredential(credentialIndex, creator, modifier, credentialStatus, credentialType,
						   secret);
}

#ifdef CONFIG_LOCK_SCHEDULES

DlStatus BoltLockManager::GetWeekDaySchedule(uint8_t weekdayIndex, uint16_t userIndex,
					     EmberAfPluginDoorLockWeekDaySchedule &schedule)
{
	return AccessMgr::Instance().GetWeekDaySchedule(weekdayIndex, userIndex, schedule);
}

DlStatus BoltLockManager::SetWeekDaySchedule(uint8_t weekdayIndex, uint16_t userIndex, DlScheduleStatus status,
					     DaysMaskMap daysMask, uint8_t startHour, uint8_t startMinute,
					     uint8_t endHour, uint8_t endMinute)
{
	return AccessMgr::Instance().SetWeekDaySchedule(weekdayIndex, userIndex, status, daysMask, startHour,
							startMinute, endHour, endMinute);
}

DlStatus BoltLockManager::GetYearDaySchedule(uint8_t yearDayIndex, uint16_t userIndex,
					     EmberAfPluginDoorLockYearDaySchedule &schedule)
{
	return AccessMgr::Instance().GetYearDaySchedule(yearDayIndex, userIndex, schedule);
}

DlStatus BoltLockManager::SetYearDaySchedule(uint8_t yeardayIndex, uint16_t userIndex, DlScheduleStatus status,
					     uint32_t localStartTime, uint32_t localEndTime)
{
	return AccessMgr::Instance().SetYearDaySchedule(yeardayIndex, userIndex, status, localStartTime, localEndTime);
}

DlStatus BoltLockManager::GetHolidaySchedule(uint8_t holidayIndex, EmberAfPluginDoorLockHolidaySchedule &schedule)
{
	return AccessMgr::Instance().GetHolidaySchedule(holidayIndex, schedule);
}

DlStatus BoltLockManager::SetHolidaySchedule(uint8_t holidayIndex, DlScheduleStatus status, uint32_t localStartTime,
					     uint32_t localEndTime, OperatingModeEnum operatingMode)
{
	return AccessMgr::Instance().SetHolidaySchedule(holidayIndex, status, localStartTime, localEndTime,
							operatingMode);
}

#endif /* CONFIG_LOCK_SCHEDULES */

bool BoltLockManager::ValidatePIN(const Optional<ByteSpan> &pinCode, OperationErrorEnum &err)
{
	return AccessMgr::Instance().ValidatePIN(pinCode, err);
}

void BoltLockManager::SetRequirePIN(bool require)
{
	return AccessMgr::Instance().SetRequirePIN(require);
}
bool BoltLockManager::GetRequirePIN()
{
	return AccessMgr::Instance().GetRequirePIN();
}

void BoltLockManager::Lock(OperationSource source)
{
	VerifyOrReturn(mState != State::kLockingCompleted);
	SetState(State::kLockingInitiated, source);

	mActuatorOperationSource = source;
	k_timer_start(&mActuatorTimer, K_MSEC(kActuatorMovementTimeMs), K_NO_WAIT);
}

void BoltLockManager::Unlock(OperationSource source)
{
	VerifyOrReturn(mState != State::kUnlockingCompleted);
	SetState(State::kUnlockingInitiated, source);

	mActuatorOperationSource = source;
	k_timer_start(&mActuatorTimer, K_MSEC(kActuatorMovementTimeMs), K_NO_WAIT);
}

void BoltLockManager::ActuatorTimerEventHandler(k_timer *timer)
{
	/*
	 * The timer event handler is called in the context of the system clock ISR.
	 * Post an event to the application task queue to process the event in the
	 * context of the application thread.
	 */

	BoltLockManagerEvent event;
	event.manager = static_cast<BoltLockManager *>(k_timer_user_data_get(timer));
	Nrf::PostTask([event] { ActuatorAppEventHandler(event); });
}

void BoltLockManager::ActuatorAppEventHandler(const BoltLockManagerEvent &event)
{
	BoltLockManager *lock = reinterpret_cast<BoltLockManager *>(event.manager);

	switch (lock->mState) {
	case State::kLockingInitiated:
		lock->SetState(State::kLockingCompleted, lock->mActuatorOperationSource);
		break;
	case State::kUnlockingInitiated:
		lock->SetState(State::kUnlockingCompleted, lock->mActuatorOperationSource);
		break;
	default:
		break;
	}
}

void BoltLockManager::SetState(State state, OperationSource source)
{
	mState = state;

	if (mStateChangeCallback != nullptr) {
		mStateChangeCallback(state, source);
	}
}
```

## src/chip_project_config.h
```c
/*
 * Copyright (c) 2021 Nordic Semiconductor ASA
 *
 * SPDX-License-Identifier: LicenseRef-Nordic-5-Clause
 */

/**
 *    @file
 *          Example project configuration file for CHIP.
 *
 *          This is a place to put application or project-specific overrides
 *          to the default configuration values for general CHIP features.
 *
 */

#pragma once

#define CHIP_DEVICE_CONFIG_CERTIFICATION_DECLARATION                                                                   \
	{                                                                                                              \
		0x30, 0x81, 0xe8, 0x06, 0x09, 0x2a, 0x86, 0x48, 0x86, 0xf7, 0x0d, 0x01, 0x07, 0x02, 0xa0, 0x81, 0xda,  \
			0x30, 0x81, 0xd7, 0x02, 0x01, 0x03, 0x31, 0x0d, 0x30, 0x0b, 0x06, 0x09, 0x60, 0x86, 0x48,      \
			0x01, 0x65, 0x03, 0x04, 0x02, 0x01, 0x30, 0x44, 0x06, 0x09, 0x2a, 0x86, 0x48, 0x86, 0xf7,      \
			0x0d, 0x01, 0x07, 0x01, 0xa0, 0x37, 0x04, 0x35, 0x15, 0x24, 0x00, 0x01, 0x25, 0x01, 0xf1,      \
			0xff, 0x36, 0x02, 0x05, 0x06, 0x80, 0x18, 0x24, 0x03, 0x0a, 0x2c, 0x04, 0x13, 0x5a, 0x49,      \
			0x47, 0x32, 0x30, 0x31, 0x34, 0x32, 0x5a, 0x42, 0x33, 0x33, 0x30, 0x30, 0x30, 0x33, 0x2d,      \
			0x32, 0x34, 0x24, 0x05, 0x00, 0x24, 0x06, 0x00, 0x25, 0x07, 0x94, 0x26, 0x24, 0x08, 0x01,      \
			0x18, 0x31, 0x7d, 0x30, 0x7b, 0x02, 0x01, 0x03, 0x80, 0x14, 0x62, 0xfa, 0x82, 0x33, 0x59,      \
			0xac, 0xfa, 0xa9, 0x96, 0x3e, 0x1c, 0xfa, 0x14, 0x0a, 0xdd, 0xf5, 0x04, 0xf3, 0x71, 0x60,      \
			0x30, 0x0b, 0x06, 0x09, 0x60, 0x86, 0x48, 0x01, 0x65, 0x03, 0x04, 0x02, 0x01, 0x30, 0x0a,      \
			0x06, 0x08, 0x2a, 0x86, 0x48, 0xce, 0x3d, 0x04, 0x03, 0x02, 0x04, 0x47, 0x30, 0x45, 0x02,      \
			0x21, 0x00, 0xd1, 0xc7, 0x84, 0xbf, 0x2d, 0x61, 0x1f, 0x66, 0x2c, 0xa4, 0x28, 0xc2, 0x11,      \
			0x08, 0x84, 0x40, 0x92, 0x54, 0x0c, 0x7f, 0x76, 0x8f, 0x77, 0x5d, 0x46, 0x7a, 0xc8, 0xfc,      \
			0x07, 0x72, 0x2a, 0xcb, 0x02, 0x20, 0x39, 0x9f, 0x1f, 0x0e, 0xcd, 0x07, 0xe4, 0x18, 0x31,      \
			0xe1, 0x34, 0x1a, 0xac, 0xfd, 0xf3, 0x5d, 0x49, 0x0d, 0xc8, 0x26, 0xac, 0xdf, 0xf8, 0x7a,      \
			0xc8, 0x13, 0x95, 0x5b, 0xb0, 0x48, 0xea, 0x27                                                 \
	}
```

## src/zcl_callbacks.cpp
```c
/*
 * Copyright (c) 2021 Nordic Semiconductor ASA
 *
 * SPDX-License-Identifier: LicenseRef-Nordic-5-Clause
 */

#include "app_task.h"
#include "bolt_lock_manager.h"

#include <app-common/zap-generated/attributes/Accessors.h>
#include <app-common/zap-generated/ids/Clusters.h>
#include <app/ConcreteAttributePath.h>
#include <app/clusters/door-lock-server/door-lock-server.h>
#include <lib/support/CodeUtils.h>

using namespace ::chip;
using namespace ::chip::app::Clusters;
using namespace ::chip::app::Clusters::DoorLock;

void MatterPostAttributeChangeCallback(const chip::app::ConcreteAttributePath &attributePath, uint8_t type,
				       uint16_t size, uint8_t *value)
{
	VerifyOrReturn(attributePath.mClusterId == DoorLock::Id &&
		       attributePath.mAttributeId == DoorLock::Attributes::LockState::Id);

	/* Post events only if current lock state is different than given */
	switch (*value) {
	case to_underlying(DlLockState::kLocked):
		BoltLockMgr().Lock(BoltLockManager::OperationSource::kRemote);
		break;
	case to_underlying(DlLockState::kUnlocked):
		BoltLockMgr().Unlock(BoltLockManager::OperationSource::kRemote);
		break;
	default:
		break;
	}
}

bool emberAfPluginDoorLockGetUser(EndpointId endpointId, uint16_t userIndex, EmberAfPluginDoorLockUserInfo &user)
{
	return BoltLockMgr().GetUser(userIndex, user);
}

bool emberAfPluginDoorLockSetUser(EndpointId endpointId, uint16_t userIndex, FabricIndex creator, FabricIndex modifier,
				  const CharSpan &userName, uint32_t uniqueId, DlUserStatus userStatus,
				  DlUserType userType, DlCredentialRule credentialRule, const DlCredential *credentials,
				  size_t totalCredentials)
{
	return BoltLockMgr().SetUser(userIndex, creator, modifier, userName, uniqueId, userStatus, userType,
				     credentialRule, credentials, totalCredentials);
}

bool emberAfPluginDoorLockGetCredential(EndpointId endpointId, uint16_t credentialIndex,
					DlCredentialType credentialType,
					EmberAfPluginDoorLockCredentialInfo &credential)
{
	return BoltLockMgr().GetCredential(credentialIndex, credentialType, credential);
}

bool emberAfPluginDoorLockSetCredential(EndpointId endpointId, uint16_t credentialIndex, FabricIndex creator,
					FabricIndex modifier, DlCredentialStatus credentialStatus,
					DlCredentialType credentialType, const ByteSpan &secret)
{
	return BoltLockMgr().SetCredential(credentialIndex, creator, modifier, credentialStatus, credentialType,
					   secret);
}

bool emberAfPluginDoorLockOnDoorLockCommand(EndpointId endpointId, const Optional<ByteSpan> &pinCode,
					    DlOperationError &err)
{
	bool result = BoltLockMgr().ValidatePIN(pinCode, err);

	/* Handle changing attribute state on command reception */
	if (result) {
		BoltLockMgr().Lock(BoltLockManager::OperationSource::kRemote);
	}

	return result;
}

bool emberAfPluginDoorLockOnDoorUnlockCommand(EndpointId endpointId, const Optional<ByteSpan> &pinCode,
					      DlOperationError &err)
{
	bool result = BoltLockMgr().ValidatePIN(pinCode, err);

	/* Handle changing attribute state on command reception */
	if (result) {
		BoltLockMgr().Unlock(BoltLockManager::OperationSource::kRemote);
	}

	return result;
}

void emberAfDoorLockClusterInitCallback(EndpointId endpoint)
{
	DoorLockServer::Instance().InitServer(endpoint);

	const auto logOnFailure = [](EmberAfStatus status, const char *attributeName) {
		if (status != EMBER_ZCL_STATUS_SUCCESS) {
			ChipLogError(Zcl, "Failed to set DoorLock %s: %x", attributeName, status);
		}
	};

	logOnFailure(DoorLock::Attributes::LockType::Set(endpoint, DlLockType::kDeadBolt), "type");
	logOnFailure(DoorLock::Attributes::NumberOfTotalUsersSupported::Set(endpoint, CONFIG_LOCK_NUM_USERS),
		     "number of users");
	logOnFailure(DoorLock::Attributes::NumberOfPINUsersSupported::Set(endpoint, CONFIG_LOCK_NUM_USERS),
		     "number of PIN users");
	logOnFailure(DoorLock::Attributes::NumberOfRFIDUsersSupported::Set(endpoint, 0), "number of RFID users");
	logOnFailure(DoorLock::Attributes::NumberOfCredentialsSupportedPerUser::Set(
			     endpoint, CONFIG_LOCK_NUM_CREDENTIALS_PER_USER),
		     "number of credentials per user");

	/*
	 * Set FeatureMap to (kUsersManagement|kPINCredentials), default is:
	 * (kUsersManagement|kAccessSchedules|kRFIDCredentials|kPINCredentials) 0x113
	 */
	logOnFailure(DoorLock::Attributes::FeatureMap::Set(endpoint, 0x101), "feature map");

	GetAppTask().UpdateClusterState(BoltLockMgr().GetState(), BoltLockManager::OperationSource::kUnspecified);
}
```
